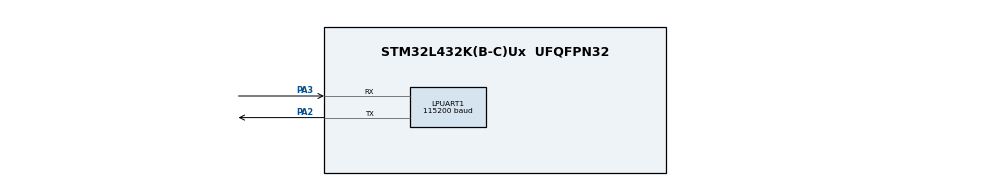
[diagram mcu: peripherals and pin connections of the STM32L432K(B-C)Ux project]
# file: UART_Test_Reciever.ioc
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LPUART1.BaudRate=115200
LPUART1.WordLength=UART_WORDLENGTH_8B
Mcu.Family=STM32L4
Mcu.Name=STM32L432K(B-C)Ux
Mcu.Package=UFQFPN32
NVIC.PriorityGroup=NVIC_PRIORITYGROUP_4
PA13\ (JTMS-SWDIO).Mode=Serial_Wire
PA13\ (JTMS-SWDIO).Signal=SYS_JTMS-SWDIO
PA14\ (JTCK-SWCLK).Mode=Serial_Wire
PA14\ (JTCK-SWCLK).Signal=SYS_JTCK-SWCLK
PA2.Mode=Asynchronous
PA2.Signal=LPUART1_TX
PA3.Mode=Asynchronous
PA3.Signal=LPUART1_RX
ProjectManager.HeapSize=0x200
ProjectManager.StackSize=0x400
ProjectManager.TargetToolchain=STM32CubeIDE
RCC.HSE_VALUE=8000000
RCC.HSI48_VALUE=48000000
RCC.HSI_VALUE=16000000
RCC.LSE_VALUE=32768
RCC.MSI_VALUE=4000000
RCC.VCOOutputFreq_Value=32000000
board=custom

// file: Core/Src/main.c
/* USER CODE BEGIN Header */
/**
  ******************************************************************************
  * @file           : main.c
  * @brief          : Main program body
  ******************************************************************************
  * @attention
  *
  * Copyright (c) 2024 STMicroelectronics.
  * All rights reserved.
  *
  * This software is licensed under terms that can be found in the LICENSE file
  * in the root directory of this software component.
  * If no LICENSE file comes with this software, it is provided AS-IS.
  *
  ******************************************************************************
  */
/* USER CODE END Header */
#include "main.h"

UART_HandleTypeDef hlpuart1;

/* USER CODE BEGIN PV */
uint8_t recievedData1;
uint8_t recievedData2[4];
/* USER CODE END PV */

void SystemClock_Config(void);
static void MX_GPIO_Init(void);
static void MX_LPUART1_UART_Init(void);

int main(void)
{

  /* MCU Configuration--------------------------------------------------------*/

  /* Reset of all peripherals, Initializes the Flash interface and the Systick. */
  HAL_Init();

  /* Configure the system clock */
  SystemClock_Config();

  /* Initialize all configured peripherals */
  MX_GPIO_Init();
  MX_LPUART1_UART_Init();

  /* Infinite loop */
  while (1)
  {
	  HAL_UART_Receive(&hlpuart1, &recievedData1, sizeof(recievedData1), 1000);

  }
}

void SystemClock_Config(void)
{
  RCC_OscInitTypeDef RCC_OscInitStruct = {0};
  RCC_ClkInitTypeDef RCC_ClkInitStruct = {0};

  /** Configure the main internal regulator output voltage
  */
  if (HAL_PWREx_ControlVoltageScaling(PWR_REGULATOR_VOLTAGE_SCALE1) != HAL_OK)
  {
    Error_Handler();
  }

  /** Initializes the RCC Oscillators according to the specified parameters
  * in the RCC_OscInitTypeDef structure.
  */
  RCC_OscInitStruct.OscillatorType = RCC_OSCILLATORTYPE_MSI;
  RCC_OscInitStruct.MSIState = RCC_MSI_ON;
  RCC_OscInitStruct.MSICalibrationValue = 0;
  RCC_OscInitStruct.MSIClockRange = RCC_MSIRANGE_6;
  RCC_OscInitStruct.PLL.PLLState = RCC_PLL_NONE;
  if (HAL_RCC_OscConfig(&RCC_OscInitStruct) != HAL_OK)
  {
    Error_Handler();
  }

  /** Initializes the CPU, AHB and APB buses clocks
  */
  RCC_ClkInitStruct.ClockType = RCC_CLOCKTYPE_HCLK|RCC_CLOCKTYPE_SYSCLK
                              |RCC_CLOCKTYPE_PCLK1|RCC_CLOCKTYPE_PCLK2;
  RCC_ClkInitStruct.SYSCLKSource = RCC_SYSCLKSOURCE_MSI;
  RCC_ClkInitStruct.AHBCLKDivider = RCC_SYSCLK_DIV1;
  RCC_ClkInitStruct.APB1CLKDivider = RCC_HCLK_DIV1;
  RCC_ClkInitStruct.APB2CLKDivider = RCC_HCLK_DIV1;

  if (HAL_RCC_ClockConfig(&RCC_ClkInitStruct, FLASH_LATENCY_0) != HAL_OK)
  {
    Error_Handler();
  }
}

static void MX_LPUART1_UART_Init(void)
{

  hlpuart1.Instance = LPUART1;
  hlpuart1.Init.BaudRate = 115200;
  hlpuart1.Init.WordLength = UART_WORDLENGTH_8B;
  hlpuart1.Init.StopBits = UART_STOPBITS_1;
  hlpuart1.Init.Parity = UART_PARITY_NONE;
  hlpuart1.Init.Mode = UART_MODE_TX_RX;
  hlpuart1.Init.HwFlowCtl = UART_HWCONTROL_NONE;
  hlpuart1.Init.OneBitSampling = UART_ONE_BIT_SAMPLE_DISABLE;
  hlpuart1.AdvancedInit.AdvFeatureInit = UART_ADVFEATURE_NO_INIT;
  if (HAL_UART_Init(&hlpuart1) != HAL_OK)
  {
    Error_Handler();
  }

}

static void MX_GPIO_Init(void)
{

  /* GPIO Ports Clock Enable */
  __HAL_RCC_GPIOA_CLK_ENABLE();

}

void Error_Handler(void)
{
  __disable_irq();
  while (1)
  {
  }
}
